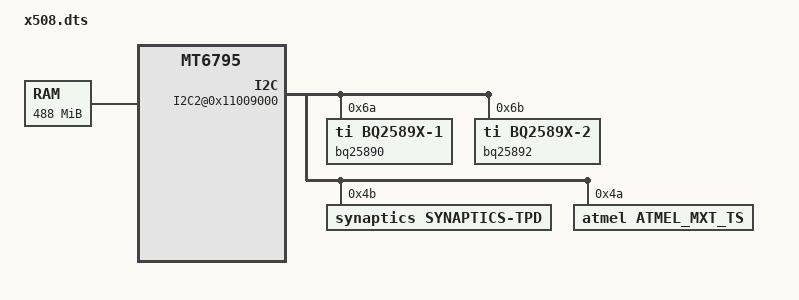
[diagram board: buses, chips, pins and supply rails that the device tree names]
/*
 * Mediatek's MT6795 SoC device tree source
 *
 * Copyright (c) 2013 MediaTek Co., Ltd.
 *              http://www.mediatek.com
 *
 */

/dts-v1/;

/include/ "mt6795.dtsi"
/include/ "cust_eint.dtsi"
/ {

	memory@00000000 {
		device_type = "memory";
		reg = <0 0x40000000 0 0x1E800000>;
	};

	bus {
		I2C2@0x11009000 {
		bq25890@6A{
		    compatible = "ti,bq2589x-1";
		    reg = <0x6A>;
		    ti,bq2589x,vbus-volt-high-level = <8700>;/* tune adapter to output 9v */
		    ti,bq2589x,vbus-volt-low-level = <4400>;/* tune adapter to output 5v */
		    ti,bq2589x,vbat-min-volt-to-tuneup = <3000>;
	 
		};

		bq25892@6B{
		    compatible = "ti,bq2589x-2";
		    reg = <0x6B>;
	      };

		synaptics-tpd@4b{
                    compatible = "synaptics,synaptics-tpd";
                    reg = <0x4B>;
              };

		atmel_mxt_ts@4a{
			compatible = "atmel,atmel_mxt_ts";
			reg = <0x4a>;
			atmel,cfg_name = "30AA.cfg";
			atmel,fw_version = "30AA.fw";
			atmel,input_name = "atmel_mxt_ts";
			linux,gpio-keymap = <158 580 172>;
			atmel,cfg_1 {
				atmel,type = <0x01>;
				atmel,family-id = <0xA4>;
				atmel,variant-id = <0x02>;
				atmel,version = <0x30>;
				atmel,build = <0xAA>;
				atmel,config-year = <0x0F>;
				atmel,config-month = <0x0B>;
				atmel,config-date = <0x03>;
				atmel,config = [
					00 25 00 00 00 82 00 00 00 00 00 00 00 00 00 00 00 00 00 00 00 00 00 00 00 00 00 00 00 00 00 00 00 00 00 00 00 00 00 00 00 00 00 00 00 00 00
					00 00 00 00 00 00 00 00 00 00 00 00 00 00 00 00 00 00 00 00 00 00 00 00 00 00 00 00 00 00 00 00 00 00 00 00 00 00 00 00 00 00 00 00 00 00 00
					00 00 00 00 00 00 00 00 00 00 00 00 00 00 00 00 00 00 00 00 00 00 00 00 00 00 00 00 00 00 00 00 00 00 00 00 00 00 00 00 00 00 00 2C 00 00 00
					01 00 00 05 00 00 00 0B FF 00 00 00 00 00 00 00 00 00 FF 00 06 00 00 00 0700 00 00 00 00 00 00 00 44 00 00 00 49 00 00 00 00 00 00 00 00 00
					00 00 00 00 00 00 00 00 00 00 00 00 00 00 00 00 00 00 00 00 00 00 00 00 00 00 00 00 00 00 00 00 00 00 00 00 00 00 00 00 00 00 00 00 00 00 00 00 00 00 00 00 00 00 00 00 00 00 00 00 00 00 00 00
					00 26 00 00 00 40 00 30 AA 0F 0B 03 00 00 00 00 00 00 00 00 00 00 00 00 00 00 00 00 00 00 00 00 00 00 00 00 00 00 00 00 00 00 00 00 00 00 00 00 00 00 00 00 00 00 00 00 00 00 00 00 00 00 00 00 00 00 00 00 00 00
					00 47 00 00 00 C8 00 00 00 00 00 00 00 00 00 00 00 00 00 00 00 00 00 00 00 00 00 00 00 00 00 00 00 00 00 00 00 00 00 00 00 00 00 00 00 00 00 00 00 00 00 00 00 00 00 00 00 00 00 00 00 00 00 00 00 00 00 00 00 00 00 00 00 00 00 00 00 00 00 00 00 00 00 00 00 00 00 00 00 00 00 00 00 00 00 00 00 00 00 00 00 00 00 00 00 00 00 00 00 00 00 00 00 00 00 00 00 00 00 00 00 00 00 00 00 00 00 00 00 00 00 00 00 00 00 00 00 00 00 00 00 00 00 00 00 00 00 00 00 00 00 00 00 00 00 00 00 00 00 00 00 00 00 00 00 00 00 00 00 00 00 00 00 00 00 00 00 00 00 00 00 00 00 00 00 00 00 00 00 00 00 00 00 00 00 00 00 00 00 00 00 00 00 00 00 00
					00 6E 00 00 00 28 D9 08 A1 0A 19 0A E9 0B 59 0A A9 0B A1 09 89 0B C9 09 21 09 99 08 49 08 89 06 51 06 D1 03 01 00 01 00 01 00 01 00 01 00
					00 6E 00 01 00 28 01 00 01 00 01 00 01 00 01 00 01 00 01 00 01 00 01 00 01 00 01 00 01 00 01 00 01 00 01 00 01 00 01 00 01 00 01 00 01 00
					00 6E 00 02 00 28 01 00 01 00 01 00 01 00 01 00 01 00 01 00 01 00 01 00 01 00 01 00 01 00 01 00 01 00 01 00 01 00 01 00 01 00 01 00 01 00
					00 6E 00 03 00 28 C1 08 21 0A C9 0A 29 0B 71 0B 11 0B F9 09 D1 0B 19 09 E9 09 99 07 E9 08 D9 05 E9 06 D1 03 01 00 01 00 01 00 01 00 01 00
					00 6E 00 04 00 28 00 00 00 00 00 00 00 00 00 00 00 00 00 00 00 00 00 00 00 00 00 00 00 00 00 00 00 00 00 00 00 00 00 00 00 00 00 00 00 00
					00 6E 00 05 00 28 00 00 00 00 00 00 00 00 00 00 00 00 00 00 00 00 00 00 00 00 00 00 00 00 00 00 00 00 00 00 00 00 00 00 00 00 00 00 00 00
					00 6E 00 06 00 28 0B 03 FB 02 FB 02 F3 02 F3 02 F3 02 FB 02 EB 02 F3 02 FB 02 0B 03 0B 03 1B 03 1B 03 33 03 03 00 03 00 03 00 03 00 03 00
					00 6E 00 07 00 28 03 00 03 00 03 00 03 00 03 00 03 00 03 00 03 00 03 00 03 00 03 00 03 00 03 00 03 00 03 00 03 00 03 00 03 00 03 00 03 00
					00 6E 00 08 00 28 03 00 03 00 03 00 03 00 03 00 03 00 03 00 03 00 03 00 03 00 03 00 03 00 03 00 03 00 03 00 03 00 03 00 03 00 03 00 03 00
					00 07 00 00 00 05 FF FF 1E 40 00
					00 08 00 00 00 0F 2D 00 14 0A 00 00 FF 01 00 00 0B 01 01 01 02
					00 0F 00 00 00 0B 83 1A 0F 01 03 00 08 32 02 00 00
					00 12 00 00 00 02 00 00
					00 13 00 00 00 06 00 00 00 00 00 00
					00 19 00 00 00 10 03 00 48 71 08 52 48 71 08 52 FF 70 17 70 17 00
					00 28 00 00 00 07 31 03 03 00 00 00 01
					00 2A 00 00 00 0E 21 00 80 32 FF 05 00 1E 05 02 C8 00 00 00
					00 2B 00 00 00 11 00 00 00 00 00 00 00 00 00 00 00 00 00 00 00 00 00
					00 2E 00 00 00 0C 00 00 18 08 01 00 00 50 00 01 00 00
					00 2F 00 00 00 2F 00 00 00 00 00 00 00 00 00 00 00 00 00 00 00 00 00 00 00 00 00 00 00 00 00 00 00 00 00 00 00 00 00 00 00 00 00 00 00 00 00 00 00 00 00 00 00
					00 38 00 00 00 24 00 00 00 24 00 00 00 00 00 00 00 00 00 00 00 00 00 00 00 00 00 00 00 00 00 00 00 00 00 00 00 00 00 00 00 00
					00 3D 00 00 00 05 00 00 00 00 00
					00 3D 00 01 00 05 00 00 00 00 00
					00 3D 00 02 00 05 00 00 00 00 00
					00 3D 00 03 00 05 00 00 00 00 00
					00 3D 00 04 00 05 00 00 00 00 00
					00 3D 00 05 00 05 00 00 00 00 00
					00 41 00 00 00 17 81 0A 00 00 00 00 00 00 00 00 0A 00 00 00 00 00 00 21 00 00 00 00 00
					00 41 00 01 00 17 00 00 00 00 00 00 00 00 00 00 00 00 00 00 00 00 00 00 00 00 00 00 00
					00 41 00 02 00 17 00 00 00 00 00 00 00 00 00 00 00 00 00 00 00 00 00 00 00 00 00 00 00
					00 46 00 00 00 0A 00 00 00 00 00 00 00 00 00 00
					00 46 00 01 00 0A 00 00 00 00 00 00 00 00 00 00
					00 46 00 02 00 0A 00 00 00 00 00 00 00 00 00 00
					00 46 00 03 00 0A 00 00 00 00 00 00 00 00 00 00
					00 46 00 04 00 0A 00 00 00 00 00 00 00 00 00 00
					00 46 00 05 00 0A 00 00 00 00 00 00 00 00 00 00
					00 46 00 06 00 0A 00 00 00 00 00 00 00 00 00 00
					00 46 00 07 00 0A 00 00 00 00 00 00 00 00 00 00
					00 46 00 08 00 0A 00 00 00 00 00 00 00 00 00 00
					00 46 00 09 00 0A 00 00 00 00 00 00 00 00 00 00
					00 46 00 0A 00 0A 00 00 00 00 00 00 00 00 00 00
					00 46 00 0B 00 0A 00 00 00 00 00 00 00 00 00 00
					00 46 00 0C 00 0A 00 00 00 00 00 00 00 00 00 00
					00 46 00 0D 00 0A 00 00 00 00 00 00 00 00 00 00
					00 46 00 0E 00 0A 00 00 00 00 00 00 00 00 00 00
					00 46 00 0F 00 0A 00 00 00 00 00 00 00 00 00 00
					01 46 00 10 00 0A 00 00 00 00 00 00 00 00 00 00
					00 46 00 11 00 0A 00 00 00 00 00 00 00 00 00 00
					00 46 00 12 00 0A 00 00 00 00 00 00 00 00 00 00
					00 46 00 13 00 0A 00 00 00 00 00 00 00 00 00 00
					00 46 00 14 00 0A 00 00 00 00 00 00 00 00 00 00
					00 46 00 15 00 0A 00 00 00 00 00 00 00 00 00 00
					00 46 00 16 00 0A 00 00 00 00 00 00 00 00 00 00
					00 46 00 17 00 0A 00 00 00 00 00 00 00 00 00 00
					00 46 00 18 00 0A 00 00 00 00 00 00 00 00 00 00
					00 46 00 19 00 0A 00 00 00 00 00 00 00 00 00 00
					00 46 00 1A 00 0A 00 00 00 00 00 00 00 00 00 00
					00 46 00 1B 00 0A 00 00 00 00 00 00 00 00 00 00
					00 46 00 1C 00 0A 00 00 00 00 00 00 00 00 00 00
					00 46 00 1D 00 0A 00 00 00 00 00 00 00 00 00 00
					00 46 00 1E 00 0A 00 00 00 00 00 00 00 00 00 00
					00 46 00 1F 00 0A 00 00 00 00 00 00 00 00 00 00
					00 46 00 20 00 0A 00 00 00 00 00 00 00 00 00 00
					00 46 00 21 00 0A 00 00 00 00 00 00 00 00 00 00
					00 46 00 22 00 0A 00 00 00 00 00 00 00 00 00 00
					00 46 00 23 00 0A 00 00 00 00 00 00 00 00 00 00
					00 46 00 24 00 0A 00 00 00 00 00 00 00 00 00 00
					00 46 00 25 00 0A 00 00 00 00 00 00 00 00 00 00
					00 46 00 26 00 0A 00 00 00 00 00 00 00 00 00 00
					00 46 00 27 00 0A 00 00 00 00 00 00 00 00 00 00
					00 48 00 00 00 59 FD 00 00 01 00 05 0A 05 05 07 0A 14 02 04 20 50 0D 0C 36 05 00 00 00 00 00 00 0C 0C 0C 0C 0C 0C 0C 0C 0C 0C 00 00 19 00 01 06 0E 1D 25 2E 10 10 10 10 10 10 10 10 10 10 00 0F 23 11 0F 06 0E 1D 25 2E 40 40 40 40 40 40 40 40 40 40 00 1C 00 11 00 08 03 03 02 00 00 00 00
					00 4D 00 00 00 02 00 00
					00 4E 00 00 00 0C 84 04 00 00 19 00 19 00 8C 00 00 00
					00 4F 00 00 00 04 00 00 00 00
					00 4F 00 01 00 04 00 00 00 00
					00 4F 00 02 00 04 00 00 00 00
					00 50 00 00 00 0E 03 22 7D 3C 0F 45 00 0F 01 01 00 00 00 00
					00 51 00 00 00 12 00 00 00 00 00 00 00 00 00 00 00 00 00 00 00 00 00 00
					00 51 00 01 00 12 00 00 00 00 00 00 00 00 00 00 00 00 00 00 00 00 00 00
					00 54 00 00 00 04 00 00 00 00
					00 5D 00 00 00 1E 0F 00 00 37 04 00 00 7F 07 00 00 00 00 00 00 00 00 00 00 00 64 00 64 00 01 1E 01 1E 00 00
					00 63 00 00 00 0C 00 00 00 00 00 00 00 00 00 00 00 00
					00 64 00 00 00 3E 83 30 00 06 00 00 0A 88 00 1A 2D 00 00 7F 07 26 21 10 5A 00 0F 2D 03 03 37 04 15 40 0C 07 28 0F 14 00 00 14 3C 14 00 01 01 01 00 0A 42 DC 1E 05 00 01 00 00 00 03 9B 21 00 00 00 00 00 00
					00 65 00 00 00 20 00 00 00 00 00 00 00 00 00 00 00 00 00 00 00 00 00 00 00 00 00 00 00 00 00 00 00 00 00 00 00 00
					00 68 00 00 00 0B 01 00 46 0F 23 03 18 1E 0F 0F 03
					00 6C 00 00 00 4B 00 00 00 00 00 00 00 00 00 00 00 00 00 00 00 00 00 00 00 00 00 00 00 00 00 00 00 00 00 00 00 00 00 00 00 00 00 00 00 00 00 00 00 00 00 00 00 00 00 00 00 00 00 00 00 00 00 00 00 00 00 00 00 00 00 00 00 00 00 00 00 00 00 00 00
					00 6D 00 00 00 09 42 00 05 00 00 00 00 00 03
					00 6F 00 00 00 1E 00 00 32 32 0C 0C 0F 05 00 FF 00 00 00 00 00 00 00 00 1E 00 33 32 00 00 00 01 00 00 00 00
					00 6F 00 01 00 1E 00 00 00 00 00 00 00 00 00 00 00 00 00 00 00 00 00 00 00 00 00 00 00 00 00 01 00 00 00 00
					00 6F 00 02 00 1E 00 00 32 32 0C 0C 0F 03 00 00 00 00 00 00 00 00 00 00 00 00 00 00 00 00 00 01 00 00 00 00
					00 70 00 00 00 05 00 00 00 00 00
					00 70 00 01 00 05 00 00 00 00 00
					00 71 00 00 00 03 05 02 06
					00 73 00 00 00 14 00 00 00 00 00 00 00 00 00 00 00 00 00 00 00 00 00 00 00 00
					00 74 00 00 00 FF 00 00 00 00 00 00 00 00 00 00 00 00 00 00 00 00 00 00 00 00 00 00 00 00 00 00 00 00 00 00 00 00 00 00 00 00 00 00 00 00 00 00 00 00 00 00 00 00 00 00 00 00 00 00 00 00 00 00 00 00 00 00 00 00 00 00 00 00 00 00 00 00 00 00 00 00 00 00 00 00 00 00 00 00 00 00 00 00 00 00 00 00 00 00 00 00 00 00 00 00 00 00 00 00 00 00 00 00 00 00 00 00 00 00 00 00 00 00 00 00 00 00 00 00 00 00 00 00 00 00 00 00 00 00 00 00 00 00 00 00 00 00 00 00 00 00 00 00 00 00 00 00 00 00 00 00 00 00 00 00 00 00 00 00 00 00 00 00 00 00 00 00 00 00 00 00 00 00 00 00 00 00 00 00 00 00 00 00 00 00 00 00 00 00 00 00 00 00 00 00 00 00 00 00 00 00 00 00 00 00 00 00 00 00 00 00 00 00 00 00 00 00 00 00 00 00 00 00 00 00 00 00 00 00 00 00 00 00 00 00 00 00 00 00 00 00 00 00 00 00 00 00 00 00 00
					00 79 00 00 00 03 00 00 00
					00 7C 00 00 00 07 0B 10 00 00 1B 41 64
					00 7D 00 00 00 01 00
					];
			};
			atmel,cfg_2 {
				atmel,type = <0x00>;
				atmel,family-id = <0xA4>;
				atmel,variant-id = <0x02>;
				atmel,version = <0x30>;
				atmel,build = <0xAA>;
				atmel,config-year = <0x0F>;
				atmel,config-month = <0x0B>;
				atmel,config-date = <0x03>;
				atmel,config = [00 25 00 00 00 82 00 00 00 00 00 00 00 00 00 00 00 00 00 00 00 00 00 00 00 00 00 00 00 00 00 00 00 00 00 00 00 00 00 00 00 00 00 00 00 00 00 00 00 00 00 00 00 00 00 00 00 00 00 00 00 00 00 00 00 00 00 00 00 00 00 00 00 00 00 00 00 00 00 00 00 00 00 00 00 00 00 00 00 00 00 00 00 00 00 00 00 00 00 00 00 00 00 00 00 00 00 00 00 00 00 00 00 00 00 00 00 00 00 00 00 00 00 00 00 00 00 00 00 00 00 00 00 00 00 00
					00 2C 00 00 00 01 00
					00 05 00 00 00 0B FF 00 00 00 00 00 00 00 00 00 FF
					00 06 00 00 00 07 00 00 00 00 00 00 00
					00 44 00 00 00 49 00 00 00 00 00 00 00 00 00 00 00 00 00 00 00 00 00 00 00 00 00 00 00 00 00 00 00 00 00 00 00 00 00 00 00 00 00 00 00 00 00 00 00 00 00 00 00 00 00 00 00 00 00 00 00 00 00 00 00 00 00 00 00 00 00 00 00 00 00 00 00 00 00
					00 26 00 00 00 40 00 30 AA 0F 0B 03 00 00 00 00 00 00 00 00 00 00 00 00 00 00 00 00 00 00 00 00 00 00 00 00 00 00 00 00 00 00 00 00 00 00 00 00 00 00 00 00 00 00 00 00 00 00 00 00 00 00 00 00 00 00 00 00 00 00
					00 47 00 00 00 C8 00 00 00 00 00 00 00 00 00 00 00 00 00 00 00 00 00 00 00 00 00 00 00 00 00 00 00 00 00 00 00 00 00 00 00 00 00 00 00 00 00 00 00 00 00 00 00 00 00 00 00 00 00 00 00 00 00 00 00 00 00 00 00 00 00 00 00 00 00 00 00 00 00 00 00 00 00 00 00 00 00 00 00 00 00 00 00 00 00 00 00 00 00 00 00 00 00 00 00 00 00 00 00 00 00 00 00 00 00 00 00 00 00 00 00 00 00 00 00 00 00 00 00 00 00 00 00 00 00 00 00 00 00 00 00 00 00 00 00 00 00 00 00 00 00 00 00 00 00 00 00 00 00 00 00 00 00 00 00 00 00 00 00 00 00 00 00 00 00 00 00 00 00 00 00 00 00 00 00 00 00 00 00 00 00 00 00 00 00 00 00 00 00 00 00 00 00 00 00 00
					00 6E 00 00 00 28 D9 08 A1 0A 19 0A E9 0B 59 0A A9 0B A1 09 89 0B C9 09 21 09 99 08 49 08 89 06 51 06 D1 03 01 00 01 00 01 00 01 00 01 00
					00 6E 00 01 00 28 01 00 01 00 01 00 01 00 01 00 01 00 01 00 01 00 01 00 01 00 01 00 01 00 01 00 01 00 01 00 01 00 01 00 01 00 01 00 01 00
					00 6E 00 02 00 28 01 00 01 00 01 00 01 00 01 00 01 00 01 00 01 00 01 00 01 00 01 00 01 00 01 00 01 00 01 00 01 00 01 00 01 00 01 00 01 00
					00 6E 00 03 00 28 C1 08 21 0A C9 0A 29 0B 71 0B 11 0B F9 09 D1 0B 19 09 E9 09 99 07 E9 08 D9 05 E9 06 D1 03 01 00 01 00 01 00 01 00 01 00
					00 6E 00 04 00 28 00 00 00 00 00 00 00 00 00 00 00 00 00 00 00 00 00 00 00 00 00 00 00 00 00 00 00 00 00 00 00 00 00 00 00 00 00 00 00 00
					00 6E 00 05 00 28 00 00 00 00 00 00 00 00 00 00 00 00 00 00 00 00 00 00 00 00 00 00 00 00 00 00 00 00 00 00 00 00 00 00 00 00 00 00 00 00
					00 6E 00 06 00 28 0B 03 FB 02 FB 02 F3 02 F3 02 F3 02 FB 02 EB 02 F3 02 FB 02 0B 03 0B 03 1B 03 1B 03 33 03 03 00 03 00 03 00 03 00 03 00
					00 6E 00 07 00 28 03 00 03 00 03 00 03 00 03 00 03 00 03 00 03 00 03 00 03 00 03 00 03 00 03 00 03 00 03 00 03 00 03 00 03 00 03 00 03 00
					00 6E 00 08 00 28 03 00 03 00 03 00 03 00 03 00 03 00 03 00 03 00 03 00 03 00 03 00 03 00 03 00 03 00 03 00 03 00 03 00 03 00 03 00 03 00
					00 07 00 00 00 05 FF FF 1E 40 00
					00 08 00 00 00 0F 2D 00 14 0A 00 00 FF 01 00 00 0B 01 01 01 02
					00 0F 00 00 00 0B 83 1A 0F 01 03 00 08 32 02 00 00
					00 12 00 00 00 02 00 00
					00 13 00 00 00 06 00 00 00 00 00 00
					00 19 00 00 00 10 03 00 48 71 08 52 48 71 08 52 FF 70 17 70 17 00
					00 28 00 00 00 07 31 03 03 00 00 00 01
					00 2A 00 00 00 0E 21 00 80 32 FF 05 00 1E 05 02 C8 00 00 00
					00 2B 00 00 00 11 00 00 00 00 00 00 00 00 00 00 00 00 00 00 00 00 00
					00 2E 00 00 00 0C 00 00 18 08 01 00 00 50 00 01 00 00
					00 2F 00 00 00 2F 00 00 00 00 00 00 00 00 00 00 00 00 00 00 00 00 00 00 00 00 00 00 00 00 00 00 00 00 00 00 00 00 00 00 00 00 00 00 00 00 00 00 00 00 00 00 00
					00 38 00 00 00 24 00 00 00 24 00 00 00 00 00 00 00 00 00 00 00 00 00 00 00 00 00 00 00 00 00 00 00 00 00 00 00 00 00 00 00 00
					00 3D 00 00 00 05 00 00 00 00 00
					00 3D 00 01 00 05 00 00 00 00 00
					00 3D 00 02 00 05 00 00 00 00 00
					00 3D 00 03 00 05 00 00 00 00 00
					00 3D 00 04 00 05 00 00 00 00 00
					00 3D 00 05 00 05 00 00 00 00 00
					00 41 00 00 00 17 81 0A 00 00 00 00 00 00 00 00 0A 00 00 00 00 00 00 21 00 00 00 00 00
					00 41 00 01 00 17 00 00 00 00 00 00 00 00 00 00 00 00 00 00 00 00 00 00 00 00 00 00 00
					00 41 00 02 00 17 00 00 00 00 00 00 00 00 00 00 00 00 00 00 00 00 00 00 00 00 00 00 00
					00 46 00 00 00 0A 00 00 00 00 00 00 00 00 00 00
					00 46 00 01 00 0A 00 00 00 00 00 00 00 00 00 00
					00 46 00 02 00 0A 00 00 00 00 00 00 00 00 00 00
					00 46 00 03 00 0A 00 00 00 00 00 00 00 00 00 00
					00 46 00 04 00 0A 00 00 00 00 00 00 00 00 00 00
					00 46 00 05 00 0A 00 00 00 00 00 00 00 00 00 00
					00 46 00 06 00 0A 00 00 00 00 00 00 00 00 00 00
					00 46 00 07 00 0A 00 00 00 00 00 00 00 00 00 00
					00 46 00 08 00 0A 00 00 00 00 00 00 00 00 00 00
					00 46 00 09 00 0A 00 00 00 00 00 00 00 00 00 00
					00 46 00 0A 00 0A 00 00 00 00 00 00 00 00 00 00
					00 46 00 0B 00 0A 00 00 00 00 00 00 00 00 00 00
					00 46 00 0C 00 0A 00 00 00 00 00 00 00 00 00 00
					00 46 00 0D 00 0A 00 00 00 00 00 00 00 00 00 00
					00 46 00 0E 00 0A 00 00 00 00 00 00 00 00 00 00
					00 46 00 0F 00 0A 00 00 00 00 00 00 00 00 00 00
					00 46 00 10 00 0A 00 00 00 00 00 00 00 00 00 00
					00 46 00 11 00 0A 00 00 00 00 00 00 00 00 00 00
					00 46 00 12 00 0A 00 00 00 00 00 00 00 00 00 00
					00 46 00 13 00 0A 00 00 00 00 00 00 00 00 00 00
					00 46 00 14 00 0A 00 00 00 00 00 00 00 00 00 00
					00 46 00 15 00 0A 00 00 00 00 00 00 00 00 00 00
					00 46 00 16 00 0A 00 00 00 00 00 00 00 00 00 00
					00 46 00 17 00 0A 00 00 00 00 00 00 00 00 00 00
					00 46 00 18 00 0A 00 00 00 00 00 00 00 00 00 00
					00 46 00 19 00 0A 00 00 00 00 00 00 00 00 00 00
					00 46 00 1A 00 0A 00 00 00 00 00 00 00 00 00 00
					00 46 00 1B 00 0A 00 00 00 00 00 00 00 00 00 00
					00 46 00 1C 00 0A 00 00 00 00 00 00 00 00 00 00
					00 46 00 1D 00 0A 00 00 00 00 00 00 00 00 00 00
					00 46 00 1E 00 0A 00 00 00 00 00 00 00 00 00 00
					00 46 00 1F 00 0A 00 00 00 00 00 00 00 00 00 00
					00 46 00 20 00 0A 00 00 00 00 00 00 00 00 00 00
					00 46 00 21 00 0A 00 00 00 00 00 00 00 00 00 00
					00 46 00 22 00 0A 00 00 00 00 00 00 00 00 00 00
					00 46 00 23 00 0A 00 00 00 00 00 00 00 00 00 00
					00 46 00 24 00 0A 00 00 00 00 00 00 00 00 00 00
					00 46 00 25 00 0A 00 00 00 00 00 00 00 00 00 00
					00 46 00 26 00 0A 00 00 00 00 00 00 00 00 00 00
					00 46 00 27 00 0A 00 00 00 00 00 00 00 00 00 00
					00 48 00 00 00 59 FD 00 00 01 00 05 0A 05 05 07 0A 14 02 04 20 50 0D 0C 36 05 00 00 00 00 00 00 0C 0C 0C 0C 0C 0C 0C 0C 0C 0C 00 00 19 00 01 06 0E 1D 25 2E 10 10 10 10 10 10 10 10 10 10 00 0F 23 11 0F 06 0E 1D 25 2E 40 40 40 40 40 40 40 40 40 40 00 1C 00 11 00 08 03 03 02 00 00 00 00
					00 4D 00 00 00 02 00 00
					00 4E 00 00 00 0C 84 04 00 00 19 00 19 00 8C 00 00 00
					00 4F 00 00 00 04 00 00 00 00
					00 4F 00 01 00 04 00 00 00 00
					00 4F 00 02 00 04 00 00 00 00
					00 50 00 00 00 0E 03 22 7D 3C 0F 45 00 0F 01 01 00 00 00 00
					00 51 00 00 00 12 00 00 00 00 00 00 00 00 00 00 00 00 00 00 00 00 00 00
					00 51 00 01 00 12 00 00 00 00 00 00 00 00 00 00 00 00 00 00 00 00 00 00
					00 54 00 00 00 04 00 00 00 00
					00 5D 00 00 00 1E 0F 00 00 37 04 00 00 7F 07 00 00 00 00 00 00 00 00 00 00 00 64 00 64 00 01 1E 01 1E 00 00
					00 63 00 00 00 0C 00 00 00 00 00 00 00 00 00 00 00 00
					00 64 00 00 00 3E 83 30 00 06 00 00 0A 88 00 1A 2D 00 00 7F 07 26 21 10 5A 00 0F 2D 03 03 37 04 15 40 0C 07 28 0F 14 00 00 14 3C 14 00 01 01 01 00 0A 42 DC 1E 05 00 01 00 00 00 03 9B 21 00 00 00 00 00 00
					00 65 00 00 00 20 00 00 00 00 00 00 00 00 00 00 00 00 00 00 00 00 00 00 00 00 00 00 00 00 00 00 00 00 00 00 00 00
					00 68 00 00 00 0B 01 00 46 0F 23 03 18 1E 0F 0F 03
					00 6C 00 00 00 4B 00 00 00 00 00 00 00 00 00 00 00 00 00 00 00 00 00 00 00 00 00 00 00 00 00 00 00 00 00 00 00 00 00 00 00 00 00 00 00 00 00 00 00 00 00 00 00 00 00 00 00 00 00 00 00 00 00 00 00 00 00 00 00 00 00 00 00 00 00 00 00 00 00 00 00
					00 6D 00 00 00 09 42 00 05 00 00 00 00 00 03
					00 6F 00 00 00 1E 00 00 32 32 0C 0C 0F 05 00 FF 00 00 00 00 00 00 00 00 1E 00 33 32 00 00 00 01 00 00 00 00
					00 6F 00 01 00 1E 00 00 00 00 00 00 00 00 00 00 00 00 00 00 00 00 00 00 00 00 00 00 00 00 00 01 00 00 00 00
					00 6F 00 02 00 1E 00 00 32 32 0C 0C 0F 03 00 00 00 00 00 00 00 00 00 00 00 00 00 00 00 00 00 01 00 00 00 00
					00 70 00 00 00 05 00 00 00 00 00
					00 70 00 01 00 05 00 00 00 00 00
					00 71 00 00 00 03 05 02 06
					00 73 00 00 00 14 00 00 00 00 00 00 00 00 00 00 00 00 00 00 00 00 00 00 00 00
					00 74 00 00 00 FF 00 00 00 00 00 00 00 00 00 00 00 00 00 00 00 00 00 00 00 00 00 00 00 00 00 00 00 00 00 00 00 00 00 00 00 00 00 00 00 00 00 00 00 00 00 00 00 00 00 00 00 00 00 00 00 00 00 00 00 00 00 00 00 00 00 00 00 00 00 00 00 00 00 00 00 00 00 00 00 00 00 00 00 00 00 00 00 00 00 00 00 00 00 00 00 00 00 00 00 00 00 00 00 00 00 00 00 00 00 00 00 00 00 00 00 00 00 00 00 00 00 00 00 00 00 00 00 00 00 00 00 00 00 00 00 00 00 00 00 00 00 00 00 00 00 00 00 00 00 00 00 00 00 00 00 00 00 00 00 00 00 00 00 00 00 00 00 00 00 00 00 00 00 00 00 00 00 00 00 00 00 00 00 00 00 00 00 00 00 00 00 00 00 00 00 00 00 00 00 00 00 00 00 00 00 00 00 00 00 00 00 00 00 00 00 00 00 00 00 00 00 00 00 00 00 00 00 00 00 00 00 00 00 00 00 00 00 00 00 00 00 00 00 00 00 00 00 00 00 00 00 00 00 00 00
					00 79 00 00 00 03 00 00 00
					00 7C 00 00 00 07 0B 10 00 00 1B 41 64
					00 7D 00 00 00 01 00
					];
                };
            };
	  };
	};
};
